# CH32F203xx register map
Vendor: WCH Ltd.; File version: 1.0
Registers are 32-bit, read-write, reset 0x0 unless marked. A register's access mark holds for its fields unless they carry their own. Offsets are from the block's base; [hi:lo] are bit positions; {n}, {i} and the like mark numbered series; 'fields as' and 'values as' point back to an identical list.

## USBHD — USB register
Base 0x40023400
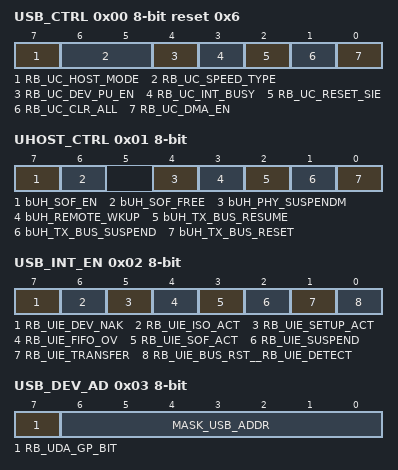
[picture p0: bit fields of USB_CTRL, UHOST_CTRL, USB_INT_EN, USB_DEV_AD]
0x00 USB_CTRL 8-bit reset 0x6 — USB base control
  [7] RB_UC_HOST_MODE — enable USB host mode: 0=device mode, 1=host mode
  [6:5] RB_UC_SPEED_TYPE — enable USB low speed: 00=full speed, 01=high speed, 10 =low speed
  [4] RB_UC_DEV_PU_EN — USB device enable and internal pullup resistance enable
  [3] RB_UC_INT_BUSY — enable automatic responding busy for device mode or automatic pause for host mode during interrupt flag UIF_TRANSFER valid
  [2] RB_UC_RESET_SIE — force reset USB SIE, need software clear
  [1] RB_UC_CLR_ALL — force clear FIFO and count of USB
  [0] RB_UC_DMA_EN — DMA enable and DMA interrupt enable for USB
0x01 UHOST_CTRL 8-bit access per field — USB HOST control
  [7] bUH_SOF_EN rw — automatically generate the SOF packet enabling control bit
  [6] bUH_SOF_FREE ro — the bus is idle
  [4] bUH_PHY_SUSPENDM rw — USB-PHY thesuspended state the internal USB-PLL is turned off
  [3] bUH_REMOTE_WKUP rw — the remoke wake-up
  [2] bUH_TX_BUS_RESUME rw — host wake up device
  [1] bUH_TX_BUS_SUSPEND rw — the host sends hang sigal
  [0] bUH_TX_BUS_RESET rw — USB host bus reset status
0x02 USB_INT_EN 8-bit — USB interrupt enable
  [7] RB_UIE_DEV_NAK — enable interrupt for NAK responded for USB device mode
  [6] RB_UIE_ISO_ACT — enable interrupt for NAK responded for USB device mode
  [5] RB_UIE_SETUP_ACT — indicate host SETUP timer action status for USB host
  [4] RB_UIE_FIFO_OV — enable interrupt for FIFO overflow
  [3] RB_UIE_SOF_ACT — indicate host SOF timer action status for USB host
  [2] RB_UIE_SUSPEND — enable interrupt for USB suspend or resume event
  [1] RB_UIE_TRANSFER — enable interrupt for USB transfer completion
  [0] RB_UIE_BUS_RST__RB_UIE_DETECT — enable interrupt for USB bus reset event for USB device mode;enable interrupt for USB device detected event for USB host mode
0x03 USB_DEV_AD 8-bit — USB device address
  [7] RB_UDA_GP_BIT — general purpose bit
  [6:0] MASK_USB_ADDR — bit mask for USB device address
0x04 USB_FRAME_NO 8-bit
  [15:0] USB_FRAME_NO
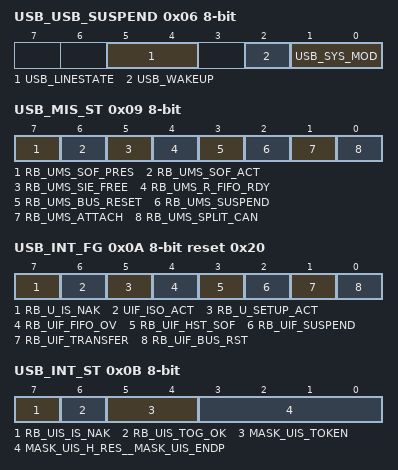
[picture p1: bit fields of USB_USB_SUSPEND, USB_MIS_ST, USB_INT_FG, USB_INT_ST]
0x06 USB_USB_SUSPEND 8-bit — indicate USB suspend status
  [5:4] USB_LINESTATE
  [2] USB_WAKEUP — remote resume
  [1:0] USB_SYS_MOD
0x08 USB_SPEED_TYPE 8-bit
  [1:0] USB_SPEED_TYPE
0x09 USB_MIS_ST 8-bit ro — USB miscellaneous status
  [7] RB_UMS_SOF_PRES — RO, indicate host SOF timer presage status
  [6] RB_UMS_SOF_ACT — RO, indicate host SOF timer action status for USB host
  [5] RB_UMS_SIE_FREE — RO, indicate USB SIE free status
  [4] RB_UMS_R_FIFO_RDY — RO, indicate USB receiving FIFO ready status (not empty)
  [3] RB_UMS_BUS_RESET — RO, indicate USB bus reset status
  [2] RB_UMS_SUSPEND — RO, indicate USB suspend status
  [1] RB_UMS_ATTACH — RO, indicate UDM level saved at device attached to USB host
  [0] RB_UMS_SPLIT_CAN — RO, indicate device attached status on USB host
0x0A USB_INT_FG 8-bit access per field reset 0x20 — USB interrupt flag
  [7] RB_U_IS_NAK ro — RO, indicate current USB transfer is NAK received
  [6] UIF_ISO_ACT rw
  [5] RB_U_SETUP_ACT rw — USB_SETUP_ACT
  [4] RB_UIF_FIFO_OV rw — FIFO overflow interrupt flag for USB, direct bit address clear or write 1 to clear
  [3] RB_UIF_HST_SOF rw — host SOF timer interrupt flag for USB host, direct bit address clear or write 1 to clear
  [2] RB_UIF_SUSPEND rw — USB suspend or resume event interrupt flag, direct bit address clear or write 1 to clear
  [1] RB_UIF_TRANSFER rw — USB transfer completion interrupt flag, direct bit address clear or write 1 to clear
  [0] RB_UIF_BUS_RST rw
0x0B USB_INT_ST 8-bit ro — USB interrupt status
  [7] RB_UIS_IS_NAK — RO, indicate current USB transfer is NAK received for USB device mode
  [6] RB_UIS_TOG_OK — RO, indicate current USB transfer toggle is OK
  [5:4] MASK_UIS_TOKEN — RO, bit mask of current token PID code received for USB device mode
  [3:0] MASK_UIS_H_RES__MASK_UIS_ENDP — RO, bit mask of current transfer handshake response for USB host mode: 0000=no response, time out from device, others=handshake response PID received;RO, bit mask of current transfer endpoint number for USB device mode
0x0C USB_RX_LEN 16-bit ro — USB receiving length
  [15:0] R16_USB_RX_LEN — length of received bytes
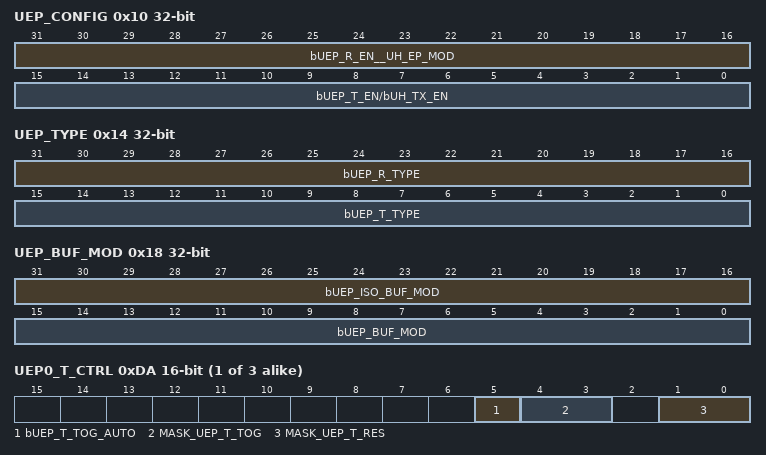
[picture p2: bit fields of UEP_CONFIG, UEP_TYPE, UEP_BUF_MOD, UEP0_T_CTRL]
0x10 UEP_CONFIG — USB endpoint configuration
  [31:16] bUEP_R_EN__UH_EP_MOD — endpoint RX enable/bUH_TX_EN
  [15:0] bUEP_T_EN/bUH_TX_EN — endpoint TX enable/bUH_TX_EN
0x14 UEP_TYPE — USB endpoint type
  [31:16] bUEP_R_TYPE — endpoint RX type
  [15:0] bUEP_T_TYPE — endpoint TX type
0x18 UEP_BUF_MOD — USB endpoint buffer mode
  [31:16] bUEP_ISO_BUF_MOD — buffer mode of USB endpoint
  [15:0] bUEP_BUF_MOD — buffer mode of USB endpoint
0x1C UEP0_DMA 16-bit — B endpoint 0 DMA buffer address
  [16:0] UEP0_DMA — endpoint 0 DMA buffer address
0x20 UEP1_RX_DMA 16-bit — endpoint 1 DMA RX buffer address
  [16:0] UEP1_RX_DMA — endpoint 1 DMA buffer address
0x24 UEP2_RX_DMA__UH_RX_DMA 16-bit — endpoint 2 DMA RX buffer address/UH_RX_DMA
  [16:0] UEP2_RX_DMA__UH_RX_DMA — endpoint 2 DMA buffer address
0x28 UEP3_RX_DMA 16-bit — endpoint 3 DMA RX buffer address
  [16:0] UEP3_RX_DMA — endpoint 3 DMA buffer address
0x2C UEP4_RX_DMA 16-bit — endpoint 4 DMA RX buffer address
  [16:0] UEP4_RX_DMA — endpoint 4 DMA buffer address
0x30 UEP5_RX_DMA 16-bit — endpoint 5 DMA RX buffer address
  [16:0] UEP5_DMA — endpoint 5 DMA buffer address
{0x1C+4i} UEP{i}_RX_DMA 16-bit (i=6..15) — endpoint {i} DMA RX buffer address
  [16:0] UEP{i}_RX_DMA — endpoint {i} DMA buffer address
0x5C UEP1_TX_DMA 16-bit — endpoint 1 DMA TX buffer address
  [16:0] UEP1_TX_DMA — endpoint 1 DMA buffer address
0x60 UEP2_TX_DMA 16-bit — endpoint 2 DMA TX buffer address
  [16:0] UEP2_TX_DMA — endpoint 2 DMA buffer address
0x64 UEP3_TX_DMA__UH_TX_DMA 16-bit — endpoint 3 DMA TX buffer address
  [16:0] UEP3_TX_DMA__UH_TX_DMA — endpoint 3 DMA buffer address
{0x58+4i} UEP{i}_TX_DMA 16-bit (i=4..11) — endpoint {i} DMA TX buffer address
  [16:0] UEP{i}_TX_DMA — endpoint {i} DMA buffer address
0x88 UEP12_TX_DMA____UH_SPLIT_DATA 16-bit — endpoint 12 DMA TX buffer address
  [16:0] UEP12_TX_DMA___UH_SPLIT_DATA — endpoint 12 DMA buffer address
{0x58+4i} UEP{i}_TX_DMA 16-bit (i=13..15) — endpoint {i} DMA TX buffer address
  [16:0] UEP{i}_TX_DMA — endpoint {i} DMA buffer address
0x98 UEP0_MAX_LEN 16-bit — endpoint 0 max acceptable length
  [10:0] UEP0_MAX_LEN
0x9C UEP1_MAX_LEN 16-bit — endpoint 1 max acceptable length
  [10:0] UEP1_MAX_LEN
0xA0 UEP2_MAX_LEN__UH_RX_MAX_LEN 16-bit — endpoint 2 max acceptable length
  [10:0] UEP2_MAX_LEN__UH_RX_MAX_LEN
0xA4 UEP3_MAX_LEN 16-bit — endpoint 3 MAX_LEN TX
  [10:0] UEP3_MAX_LEN — endpoint 3 max acceptable length
{0x98+4i} UEP{i}_MAX_LEN 16-bit (i=4..15) — endpoint {i} max acceptable length
  [10:0] UEP{i}_MAX_LEN
0xD8 UEP0_T_LEN 16-bit — endpoint 0 send the length
  [10:0] UEP0_T_LEN
{0xDA+4i} UEP{i}_T_CTRL 16-bit (i=0..2) — endpoint {i} send control
  [5] bUEP_T_TOG_AUTO — endpoint {i} synchronous trigger bit automatic filp enables the control bit
  [4:3] MASK_UEP_T_TOG — endpoint {i} synchronous trigger bit for the sender to prepare
  [1:0] MASK_UEP_T_RES — endpoint {i} control of the send response to IN transactions
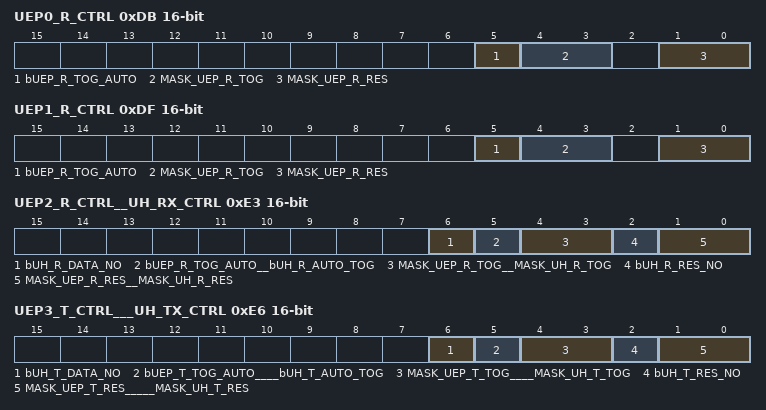
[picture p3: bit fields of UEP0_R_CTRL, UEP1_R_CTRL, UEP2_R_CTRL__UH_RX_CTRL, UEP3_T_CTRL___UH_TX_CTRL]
0xDB UEP0_R_CTRL 16-bit — endpoint 0 send control
  [5] bUEP_R_TOG_AUTO — endpoint 0 synchronous trigger bit automatic filp enables the control bit
  [4:3] MASK_UEP_R_TOG — endpoint 0 synchronous trigger bit for the accept to prepare
  [1:0] MASK_UEP_R_RES — endpoint 0 control of the accept response to OUT transactions
0xDC UEP1_T_LEN 16-bit — endpoint 1 send the length
  [10:0] UEP1_T_LEN
0xDF UEP1_R_CTRL 16-bit — endpoint 1 send control
  [5] bUEP_R_TOG_AUTO — endpoint 1 synchronous trigger bit automatic filp enables the control bit
  [4:3] MASK_UEP_R_TOG — endpoint 1 synchronous trigger bit for the accept to prepare
  [1:0] MASK_UEP_R_RES — endpoint 1 control of the accept response to OUT transactions
0xE0 UEP2_T_LEN__UH_EP_PID 16-bit — endpoint 2 send the length
  [10:0] UEP2_T_LEN__MASK_UH_ENDP__MASK_UH_TOKEN
0xE3 UEP2_R_CTRL__UH_RX_CTRL 16-bit — endpoint 2 send control
  [6] bUH_R_DATA_NO
  [5] bUEP_R_TOG_AUTO__bUH_R_AUTO_TOG — endpoint 2 synchronous trigger bit automatic filp enables the control bit
  [4:3] MASK_UEP_R_TOG__MASK_UH_R_TOG — endpoint 2 synchronous trigger bit for the accept to prepare
  [2] bUH_R_RES_NO
  [1:0] MASK_UEP_R_RES__MASK_UH_R_RES — endpoint 2 control of the accept response to OUT transactions
0xE4 UEP3_T_LEN___UH_TX_LEN_H 16-bit — endpoint 3 send the length
  [10:0] UEP3_T_LEN___UH_TX_LEN_H
0xE6 UEP3_T_CTRL___UH_TX_CTRL 16-bit — endpoint 3 send control
  [6] bUH_T_DATA_NO
  [5] bUEP_T_TOG_AUTO____bUH_T_AUTO_TOG — endpoint 3 synchronous trigger bit automatic filp enables the control bit
  [4:3] MASK_UEP_T_TOG____MASK_UH_T_TOG — endpoint 3 synchronous trigger bit for the sender to prepare
  [2] bUH_T_RES_NO
  [1:0] MASK_UEP_T_RES_____MASK_UH_T_RES — endpoint 3 control of the send response to IN transactions
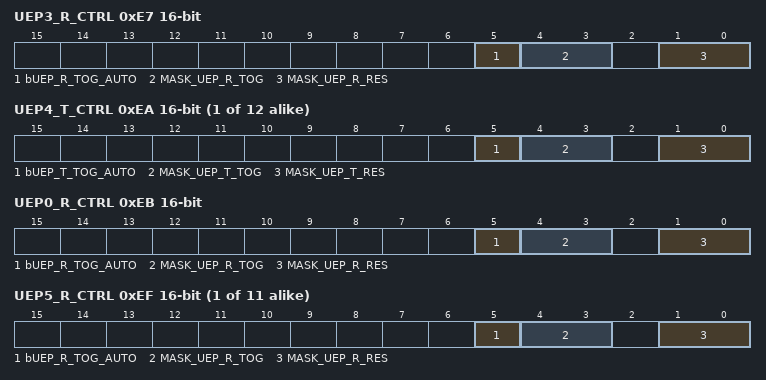
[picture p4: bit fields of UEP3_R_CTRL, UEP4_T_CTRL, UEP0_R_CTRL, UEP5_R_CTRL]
0xE7 UEP3_R_CTRL 16-bit — endpoint 3 send control
  [5] bUEP_R_TOG_AUTO — endpoint 3 synchronous trigger bit automatic filp enables the control bit
  [4:3] MASK_UEP_R_TOG — endpoint 3 synchronous trigger bit for the accept to prepare
  [1:0] MASK_UEP_R_RES — endpoint 3 control of the accept response to OUT transactions
0xE8 UEP4_T_LEN 16-bit — endpoint 4 send the length
  [10:0] UEP4_T_LEN — endpoint 0 send the length
{0xDA+4i} UEP{i}_T_CTRL 16-bit (i=4..15) — endpoint {i} send control
  fields as UEP0_T_CTRL
0xEB UEP0_R_CTRL 16-bit — endpoint 4 send control
  [5] bUEP_R_TOG_AUTO — endpoint 4 synchronous trigger bit automatic filp enables the control bit
  [4:3] MASK_UEP_R_TOG — endpoint 4 synchronous trigger bit for the accept to prepare
  [1:0] MASK_UEP_R_RES — endpoint 4 control of the accept response to OUT transactions
{0xD8+4i} UEP{i}_T_LEN 16-bit (i=5..8) — endpoint {i} send the length
  [10:0] UEP{i}_T_LEN
{0xDB+4i} UEP{i}_R_CTRL 16-bit (i=5..15) — endpoint {i} send control
  [5] bUEP_R_TOG_AUTO — endpoint {i} synchronous trigger bit automatic filp enables the control bit
  [4:3] MASK_UEP_R_TOG — endpoint {i} synchronous trigger bit for the accept to prepare
  [1:0] MASK_UEP_R_RES — endpoint {i} control of the accept response to OUT transactions
0xFC UEP9_T_LEN 16-bit — endpoint9 send the length
  [10:0] UEP9_T_LEN — endpoint 9 send the length
0x100 UEP10_T_LEN 16-bit — endpoint 10 send the length
  [10:0] UEP10_T_LEN
0x104 UEP11_T_LEN 16-bit — endpoint 11 send the length
  [10:0] UEP0_T_LEN
0x108 UEP12_T_LEN 16-bit — endpoint 12 send the length
  [10:0] UEP0_T_LEN
0x10C UEP13_T_LEN 16-bit — endpoint 13 send the length
  [10:0] UEP13_T_LEN
0x110 UEP14_T_LEN 16-bit — endpoint 14 send the length
  [10:0] UEP14_T_LEN
0x114 UEP15_T_LEN 16-bit — endpoint 15 send the length
  [10:0] UEP0_T_LEN
